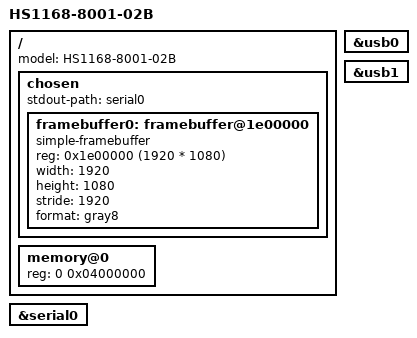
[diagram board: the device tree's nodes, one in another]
// SPDX-License-Identifier: GPL-2.0
/dts-v1/;

// Space for framebuffers:
// - chroma @ 29 MiB, size 1 MiB, all gray
// - luma   @ 30 MiB, size 2 MiB, for use by linux
/memreserve/ 0x1d00000 0x300000;

#include "m88cs8001b.dtsi"

/ {
	model = "HS1168-8001-02B";

	chosen {
		stdout-path = "serial0";
		#address-cells = <1>;
		#size-cells = <1>;
		ranges;

		// Grayscale framebuffer at the 30 MiB mark.
		framebuffer0: framebuffer@1e00000 {
		      compatible = "simple-framebuffer";
		      reg = <0x1e00000 (1920 * 1080)>;
		      width = <1920>;
		      height = <1080>;
		      stride = <1920>;
		      format = "gray8";
	      };
	};

	memory@0 {
		device_type = "memory";
		reg = <0 0x04000000>;
	};
};

&serial0 {
	status = "okay";
};

&usb0 {
	status = "okay";
};

&usb1 {
	status = "okay";
};
